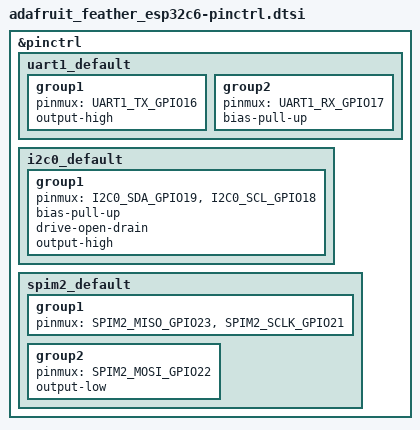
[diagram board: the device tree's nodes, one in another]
/*
 * Copyright (c) 2026 Tim Boldt
 *
 * SPDX-License-Identifier: Apache-2.0
 *
 * Pin assignments taken from the Adafruit ESP32-C6 Feather pinout:
 *   https://learn.adafruit.com/adafruit-esp32-c6-feather/pinouts
 *
 *   STEMMA QT / I2C : SDA = IO19, SCL = IO18
 *   SPI header      : SCK = IO21, MOSI = IO22, MISO = IO23
 *   UART header     : TX  = IO16, RX   = IO17
 *
 * The ESP32-C6 routes every peripheral through the GPIO matrix, so these
 * SIGxx_GPIOyy macros just pick which pad each signal lands on.
 */

#include <zephyr/dt-bindings/pinctrl/esp-pinctrl-common.h>
#include <zephyr/dt-bindings/pinctrl/esp32c6-pinctrl.h>
#include <zephyr/dt-bindings/pinctrl/esp32c6-gpio-sigmap.h>

&pinctrl {
	uart1_default: uart1_default {
		group1 {
			pinmux = <UART1_TX_GPIO16>;
			output-high;
		};
		group2 {
			pinmux = <UART1_RX_GPIO17>;
			bias-pull-up;
		};
	};

	i2c0_default: i2c0_default {
		group1 {
			pinmux = <I2C0_SDA_GPIO19>,
				 <I2C0_SCL_GPIO18>;
			bias-pull-up;
			drive-open-drain;
			output-high;
		};
	};

	/*
	 * Chip-select is not muxed here: the TFT FeatherWing and the microSD
	 * slot each need their own GPIO CS (and the TFT a DC line), so the SPI
	 * controller node uses cs-gpios instead of a hardware CS pad.
	 */
	spim2_default: spim2_default {
		group1 {
			pinmux = <SPIM2_MISO_GPIO23>,
				 <SPIM2_SCLK_GPIO21>;
		};
		group2 {
			pinmux = <SPIM2_MOSI_GPIO22>;
			output-low;
		};
	};
};
